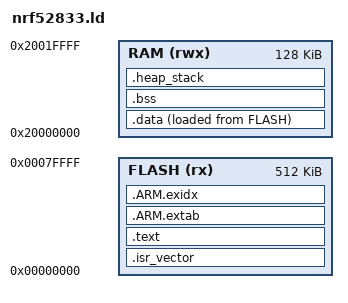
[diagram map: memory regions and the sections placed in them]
MEMORY
{
    FLASH (rx)  : ORIGIN = 0x00000000, LENGTH = 512K
    RAM   (rwx) : ORIGIN = 0x20000000, LENGTH = 128K
}

_estack = ORIGIN(RAM) + LENGTH(RAM);

SECTIONS
{
    .isr_vector :
    {
        KEEP(*(.isr_vector))
    } > FLASH

    .text :
    {
        *(.text*)
        *(.rodata*)
        KEEP(*(.init))
        KEEP(*(.fini))
        . = ALIGN(4);
    } > FLASH

    .ARM.extab :
    {
        *(.ARM.extab* .gnu.linkonce.armextab.*)
    } > FLASH

    .ARM.exidx :
    {
        __exidx_start = .;
        *(.ARM.exidx* .gnu.linkonce.armexidx.*)
        __exidx_end = .;
    } > FLASH

    . = ALIGN(4);
    _sidata = LOADADDR(.data);

    .data :
    {
        _sdata = .;
        *(.data*)
        . = ALIGN(4);
        _edata = .;
    } > RAM AT > FLASH

    .bss :
    {
        _sbss = .;
        *(.bss*)
        *(COMMON)
        . = ALIGN(4);
        _ebss = .;
    } > RAM

    .heap_stack (NOLOAD) :
    {
        . = ALIGN(8);
        . = . + 0x800;
        . = . + 0x1000;
        . = ALIGN(8);
    } > RAM

    /DISCARD/ :
    {
        *(.note*)
        *(.comment*)
    }
}
